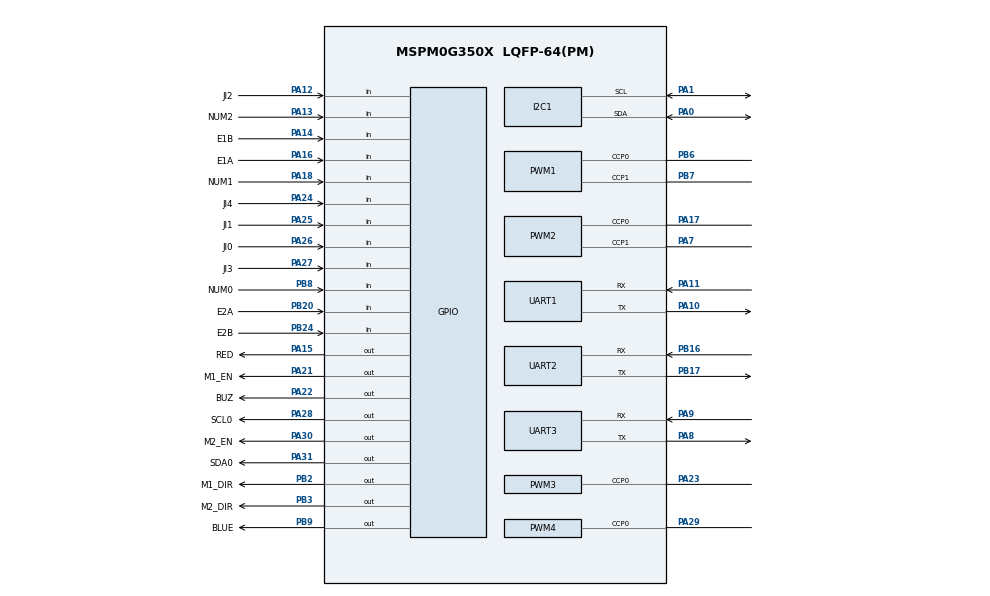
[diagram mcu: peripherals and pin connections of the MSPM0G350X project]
/**
 * @cliArgs --device "MSPM0G350X" --part "Default" --package "LQFP-64(PM)" --product "mspm0_sdk@2.01.00.03"
 * @versions {"tool":"1.21.0+3721"}
 */

/**
 * Import the modules used in this configuration.
 */
const GPIO   = scripting.addModule("/ti/driverlib/GPIO", {}, false);
const GPIO1  = GPIO.addInstance();
const GPIO2  = GPIO.addInstance();
const GPIO3  = GPIO.addInstance();
const GPIO4  = GPIO.addInstance();
const GPIO5  = GPIO.addInstance();
const GPIO6  = GPIO.addInstance();
const GPIO7  = GPIO.addInstance();
const GPIO8  = GPIO.addInstance();
const GPIO9  = GPIO.addInstance();
const I2C    = scripting.addModule("/ti/driverlib/I2C", {}, false);
const I2C1   = I2C.addInstance();
const PWM    = scripting.addModule("/ti/driverlib/PWM", {}, false);
const PWM1   = PWM.addInstance();
const PWM2   = PWM.addInstance();
const PWM3   = PWM.addInstance();
const PWM4   = PWM.addInstance();
const SYSCTL = scripting.addModule("/ti/driverlib/SYSCTL");
const TIMER  = scripting.addModule("/ti/driverlib/TIMER", {}, false);
const TIMER1 = TIMER.addInstance();
const TIMER2 = TIMER.addInstance();
const TIMER3 = TIMER.addInstance();
const UART   = scripting.addModule("/ti/driverlib/UART", {}, false);
const UART1  = UART.addInstance();
const UART2  = UART.addInstance();
const UART3  = UART.addInstance();

/**
 * Write custom configuration values to the imported modules.
 */
const divider6       = system.clockTree["PLL_CLK2X_DIV"];
divider6.divideValue = 4;

const divider7       = system.clockTree["PLL_PDIV"];
divider7.divideValue = 4;

const divider9       = system.clockTree["UDIV"];
divider9.divideValue = 2;

const multiplier2         = system.clockTree["PLL_QDIV"];
multiplier2.multiplyValue = 16;

const mux4       = system.clockTree["EXHFMUX"];
mux4.inputSelect = "EXHFMUX_XTAL";

const mux8       = system.clockTree["HSCLKMUX"];
mux8.inputSelect = "HSCLKMUX_SYSPLL2X";

const mux12       = system.clockTree["SYSPLLMUX"];
mux12.inputSelect = "zSYSPLLMUX_HFCLK";

const pinFunction4        = system.clockTree["HFXT"];
pinFunction4.inputFreq    = 40;
pinFunction4.enable       = true;
pinFunction4.HFXTStartup  = 255;
pinFunction4.HFCLKMonitor = true;

GPIO1.portSegment                        = "Lower";
GPIO1.$name                              = "LED";
GPIO1.associatedPins.create(2);
GPIO1.associatedPins[0].initialValue     = "SET";
GPIO1.associatedPins[0].ioStructure      = "SD";
GPIO1.associatedPins[0].internalResistor = "PULL_UP";
GPIO1.associatedPins[0].$name            = "BLUE";
GPIO1.associatedPins[0].pin.$assign      = "PB9";
GPIO1.associatedPins[1].$name            = "RED";
GPIO1.associatedPins[1].ioStructure      = "SD";
GPIO1.associatedPins[1].internalResistor = "PULL_DOWN";
GPIO1.associatedPins[1].pin.$assign      = "PA15";

const Board = scripting.addModule("/ti/driverlib/Board", {}, false);

GPIO2.$name                              = "KEY";
GPIO2.associatedPins.create(3);
GPIO2.associatedPins[0].direction        = "INPUT";
GPIO2.associatedPins[0].internalResistor = "PULL_UP";
GPIO2.associatedPins[0].$name            = "NUM0";
GPIO2.associatedPins[0].pin.$assign      = "PB8";
GPIO2.associatedPins[1].direction        = "INPUT";
GPIO2.associatedPins[1].internalResistor = "PULL_DOWN";
GPIO2.associatedPins[1].$name            = "NUM1";
GPIO2.associatedPins[1].pin.$assign      = "PA18";
GPIO2.associatedPins[2].$name            = "NUM2";
GPIO2.associatedPins[2].direction        = "INPUT";
GPIO2.associatedPins[2].internalResistor = "PULL_UP";
GPIO2.associatedPins[2].pin.$assign      = "PA13";

GPIO3.$name                              = "OLED";
GPIO3.associatedPins.create(2);
GPIO3.associatedPins[0].internalResistor = "PULL_UP";
GPIO3.associatedPins[0].$name            = "SCL0";
GPIO3.associatedPins[0].initialValue     = "SET";
GPIO3.associatedPins[0].pin.$assign      = "PA28";
GPIO3.associatedPins[1].internalResistor = "PULL_UP";
GPIO3.associatedPins[1].$name            = "SDA0";
GPIO3.associatedPins[1].initialValue     = "SET";
GPIO3.associatedPins[1].pin.$assign      = "PA31";

GPIO4.$name                              = "BUZZER";
GPIO4.associatedPins[0].ioStructure      = "SD";
GPIO4.associatedPins[0].internalResistor = "PULL_DOWN";
GPIO4.associatedPins[0].$name            = "BUZ";
GPIO4.associatedPins[0].pin.$assign      = "PA22";

GPIO5.$name                         = "ENCODERA";
GPIO5.associatedPins.create(2);
GPIO5.associatedPins[0].direction   = "INPUT";
GPIO5.associatedPins[0].interruptEn = true;
GPIO5.associatedPins[0].polarity    = "RISE";
GPIO5.associatedPins[0].$name       = "E1A";
GPIO5.associatedPins[0].pin.$assign = "PA16";
GPIO5.associatedPins[1].direction   = "INPUT";
GPIO5.associatedPins[1].interruptEn = true;
GPIO5.associatedPins[1].polarity    = "RISE";
GPIO5.associatedPins[1].$name       = "E1B";
GPIO5.associatedPins[1].pin.$assign = "PA14";

GPIO6.$name                              = "XUN";
GPIO6.associatedPins.create(5);
GPIO6.associatedPins[0].$name            = "JI0";
GPIO6.associatedPins[0].direction        = "INPUT";
GPIO6.associatedPins[0].internalResistor = "PULL_DOWN";
GPIO6.associatedPins[0].pin.$assign      = "PA26";
GPIO6.associatedPins[1].$name            = "JI1";
GPIO6.associatedPins[1].direction        = "INPUT";
GPIO6.associatedPins[1].internalResistor = "PULL_DOWN";
GPIO6.associatedPins[1].pin.$assign      = "PA25";
GPIO6.associatedPins[2].$name            = "JI2";
GPIO6.associatedPins[2].direction        = "INPUT";
GPIO6.associatedPins[2].internalResistor = "PULL_DOWN";
GPIO6.associatedPins[2].pin.$assign      = "PA12";
GPIO6.associatedPins[3].$name            = "JI3";
GPIO6.associatedPins[3].direction        = "INPUT";
GPIO6.associatedPins[3].internalResistor = "PULL_DOWN";
GPIO6.associatedPins[3].pin.$assign      = "PA27";
GPIO6.associatedPins[4].$name            = "JI4";
GPIO6.associatedPins[4].direction        = "INPUT";
GPIO6.associatedPins[4].internalResistor = "PULL_DOWN";
GPIO6.associatedPins[4].pin.$assign      = "PA24";

GPIO7.$name                         = "ENCODERB";
GPIO7.associatedPins.create(2);
GPIO7.associatedPins[0].$name       = "E2A";
GPIO7.associatedPins[0].direction   = "INPUT";
GPIO7.associatedPins[0].interruptEn = true;
GPIO7.associatedPins[0].polarity    = "RISE";
GPIO7.associatedPins[0].pin.$assign = "PB20";
GPIO7.associatedPins[1].$name       = "E2B";
GPIO7.associatedPins[1].direction   = "INPUT";
GPIO7.associatedPins[1].interruptEn = true;
GPIO7.associatedPins[1].polarity    = "RISE";
GPIO7.associatedPins[1].pin.$assign = "PB24";

GPIO8.$name                          = "STEP_EN";
GPIO8.port                           = "PORTA";
GPIO8.associatedPins.create(2);
GPIO8.associatedPins[0].$name        = "M1_EN";
GPIO8.associatedPins[0].initialValue = "SET";
GPIO8.associatedPins[0].pin.$assign  = "PA21";
GPIO8.associatedPins[1].$name        = "M2_EN";
GPIO8.associatedPins[1].initialValue = "SET";
GPIO8.associatedPins[1].pin.$assign  = "PA30";

GPIO9.$name                         = "STEP_DIR";
GPIO9.port                          = "PORTB";
GPIO9.associatedPins.create(2);
GPIO9.associatedPins[0].$name       = "M1_DIR";
GPIO9.associatedPins[0].pin.$assign = "PB2";
GPIO9.associatedPins[1].$name       = "M2_DIR";
GPIO9.associatedPins[1].pin.$assign = "PB3";

I2C1.$name                     = "I2C_0";
I2C1.basicEnableController     = true;
I2C1.intController             = ["RXFIFO_TRIGGER","RX_DONE","TXFIFO_TRIGGER","TX_DONE"];
I2C1.peripheral.$assign        = "I2C0";
I2C1.peripheral.sdaPin.$assign = "PA0";
I2C1.peripheral.sclPin.$assign = "PA1";
I2C1.sdaPinConfig.$name        = "ti_driverlib_gpio_GPIOPinGeneric4";
I2C1.sclPinConfig.$name        = "ti_driverlib_gpio_GPIOPinGeneric5";

PWM1.$name                      = "PWM_0";
PWM1.timerCount                 = 8000;
PWM1.pwmMode                    = "EDGE_ALIGN_UP";
PWM1.timerStartTimer            = true;
PWM1.peripheral.$assign         = "TIMG8";
PWM1.peripheral.ccp0Pin.$assign = "PB6";
PWM1.peripheral.ccp1Pin.$assign = "PB7";
PWM1.PWM_CHANNEL_0.$name        = "ti_driverlib_pwm_PWMTimerCC0";
PWM1.PWM_CHANNEL_1.$name        = "ti_driverlib_pwm_PWMTimerCC1";
PWM1.ccp0PinConfig.$name        = "ti_driverlib_gpio_GPIOPinGeneric8";
PWM1.ccp1PinConfig.$name        = "ti_driverlib_gpio_GPIOPinGeneric9";

PWM2.$name                      = "PWM_1";
PWM2.timerCount                 = 8000;
PWM2.timerStartTimer            = true;
PWM2.pwmMode                    = "EDGE_ALIGN_UP";
PWM2.peripheral.ccp0Pin.$assign = "PA17";
PWM2.peripheral.ccp1Pin.$assign = "PA7";
PWM2.PWM_CHANNEL_0.$name        = "ti_driverlib_pwm_PWMTimerCC2";
PWM2.PWM_CHANNEL_1.$name        = "ti_driverlib_pwm_PWMTimerCC3";
PWM2.ccp0PinConfig.$name        = "ti_driverlib_gpio_GPIOPinGeneric10";
PWM2.ccp1PinConfig.$name        = "ti_driverlib_gpio_GPIOPinGeneric11";

PWM3.$name                              = "STEP_M1_PWM";
PWM3.timerCount                         = 28000;
PWM3.ccIndex                            = [0];
PWM3.peripheral.$assign                 = "TIMG0";
PWM3.peripheral.ccp0Pin.$assign         = "PA23";
PWM3.PWM_CHANNEL_0.$name                = "ti_driverlib_pwm_PWMTimerCC4";
PWM3.PWM_CHANNEL_0.ccValue              = 194;
PWM3.ccp0PinConfig.$name                = "ti_driverlib_gpio_GPIOPinGeneric6";
PWM3.ccp0PinConfig.direction            = scripting.forceWrite("OUTPUT");
PWM3.ccp0PinConfig.hideOutputInversion  = scripting.forceWrite(false);
PWM3.ccp0PinConfig.onlyInternalResistor = scripting.forceWrite(false);
PWM3.ccp0PinConfig.passedPeripheralType = scripting.forceWrite("Digital");

PWM4.$name                              = "STEP_M2_PWM";
PWM4.timerCount                         = 56000;
PWM4.ccIndex                            = [0];
PWM4.peripheral.$assign                 = "TIMG6";
PWM4.peripheral.ccp0Pin.$assign         = "PA29";
PWM4.PWM_CHANNEL_0.$name                = "ti_driverlib_pwm_PWMTimerCC5";
PWM4.PWM_CHANNEL_0.ccValue              = 389;
PWM4.ccp0PinConfig.direction            = scripting.forceWrite("OUTPUT");
PWM4.ccp0PinConfig.hideOutputInversion  = scripting.forceWrite(false);
PWM4.ccp0PinConfig.onlyInternalResistor = scripting.forceWrite(false);
PWM4.ccp0PinConfig.passedPeripheralType = scripting.forceWrite("Digital");
PWM4.ccp0PinConfig.$name                = "ti_driverlib_gpio_GPIOPinGeneric7";

SYSCTL.forceDefaultClkConfig = true;
SYSCTL.clockTreeEn           = true;

TIMER1.interrupts         = ["ZERO"];
TIMER1.timerStartTimer    = true;
TIMER1.timerMode          = "PERIODIC";
TIMER1.$name              = "SYSTIMER";
TIMER1.timerClkPrescale   = 80;
TIMER1.timerPeriod        = "1ms";
TIMER1.peripheral.$assign = "TIMA1";

TIMER2.timerClkPrescale   = 79;
TIMER2.timerMode          = "PERIODIC";
TIMER2.timerPeriod        = "0.01ms";
TIMER2.timerStartTimer    = true;
TIMER2.interrupts         = ["ZERO"];
TIMER2.$name              = "TASKTIMER";
TIMER2.peripheral.$assign = "TIMA0";

TIMER3.$name              = "STEP_CTRL_TIMER";
TIMER3.interrupts         = ["ZERO"];
TIMER3.timerPeriod        = "1 ms";
TIMER3.timerMode          = "PERIODIC_UP";
TIMER3.timerStartTimer    = true;
TIMER3.peripheral.$assign = "TIMG12";

UART1.$name                    = "UART_0";
UART1.targetBaudRate           = 115200;
UART1.enabledInterrupts        = ["RX"];
UART1.peripheral.$assign       = "UART0";
UART1.peripheral.rxPin.$assign = "PA11";
UART1.peripheral.txPin.$assign = "PA10";
UART1.txPinConfig.$name        = "ti_driverlib_gpio_GPIOPinGeneric0";
UART1.rxPinConfig.$name        = "ti_driverlib_gpio_GPIOPinGeneric1";

UART2.targetBaudRate                   = 115200;
UART2.$name                            = "UART_2";
UART2.enabledInterrupts                = ["RX"];
UART2.peripheral.$assign               = "UART2";
UART2.peripheral.rxPin.$assign         = "PB16";
UART2.peripheral.txPin.$assign         = "PB17";
UART2.txPinConfig.direction            = scripting.forceWrite("OUTPUT");
UART2.txPinConfig.hideOutputInversion  = scripting.forceWrite(false);
UART2.txPinConfig.onlyInternalResistor = scripting.forceWrite(false);
UART2.txPinConfig.passedPeripheralType = scripting.forceWrite("Digital");
UART2.txPinConfig.$name                = "ti_driverlib_gpio_GPIOPinGeneric2";
UART2.rxPinConfig.hideOutputInversion  = scripting.forceWrite(false);
UART2.rxPinConfig.onlyInternalResistor = scripting.forceWrite(false);
UART2.rxPinConfig.passedPeripheralType = scripting.forceWrite("Digital");
UART2.rxPinConfig.$name                = "ti_driverlib_gpio_GPIOPinGeneric3";

UART3.$name                            = "UART_1";
UART3.targetBaudRate                   = 115200;
UART3.peripheral.$assign               = "UART1";
UART3.peripheral.rxPin.$assign         = "PA9";
UART3.peripheral.txPin.$assign         = "PA8";
UART3.txPinConfig.direction            = scripting.forceWrite("OUTPUT");
UART3.txPinConfig.hideOutputInversion  = scripting.forceWrite(false);
UART3.txPinConfig.onlyInternalResistor = scripting.forceWrite(false);
UART3.txPinConfig.passedPeripheralType = scripting.forceWrite("Digital");
UART3.txPinConfig.$name                = "UART3_TX_PINCFG";
UART3.rxPinConfig.hideOutputInversion  = scripting.forceWrite(false);
UART3.rxPinConfig.onlyInternalResistor = scripting.forceWrite(false);
UART3.rxPinConfig.passedPeripheralType = scripting.forceWrite("Digital");
UART3.rxPinConfig.$name                = "UART3_RX_PINCFG";

/**
 * Pinmux solution for unlocked pins/peripherals. This ensures that minor changes to the automatic solver in a future
 * version of the tool will not impact the pinmux you originally saw.  These lines can be completely deleted in order to
 * re-solve from scratch.
 */
pinFunction4.peripheral.$suggestSolution           = "SYSCTL";
pinFunction4.peripheral.hfxInPin.$suggestSolution  = "PA5";
pinFunction4.peripheral.hfxOutPin.$suggestSolution = "PA6";
Board.peripheral.$suggestSolution                  = "DEBUGSS";
Board.peripheral.swclkPin.$suggestSolution         = "PA20";
Board.peripheral.swdioPin.$suggestSolution         = "PA19";
PWM2.peripheral.$suggestSolution                   = "TIMG7";
